# alb32r003x register map
Vendor: ALB; Series: ALB RT SoC
CPU: ALB XF, little endian
Registers are 32-bit, access not given, reset 0x0 unless marked. A register's access mark holds for its fields unless they carry their own. Offsets are from the block's base; [hi:lo] are bit positions.

## CMPSS1
Base 0x21030000
Same registers: CMPSS2 0x21030400, CMPSS3 0x21030800, CMPSS4 0x21030C00
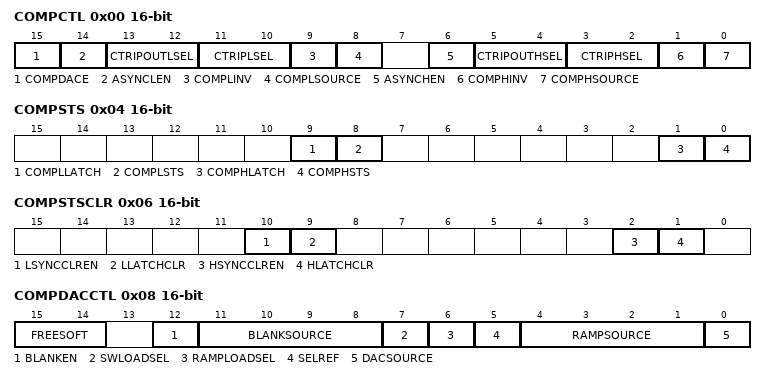
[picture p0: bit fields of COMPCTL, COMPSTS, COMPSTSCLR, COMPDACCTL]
0x00 COMPCTL 16-bit
  [15] COMPDACE — Comparator/DAC enable.
  [14] ASYNCLEN — Low comparator asynchronous path enable. Allows asynchronous
  [13:12] CTRIPOUTLSEL — Low comparator CTRIPOUTL source select.
  [11:10] CTRIPLSEL — Low comparator CTRIPL source select.
  [9] COMPLINV — Low comparator output invert.
  [8] COMPLSOURCE — Low comparator input source.
  [6] ASYNCHEN — High comparator asynchronous path enable. Allows asynchronous
  [5:4] CTRIPOUTHSEL — High comparator CTRIPOUTH source select.
  [3:2] CTRIPHSEL — High comparator CTRIPH source select.
  [1] COMPHINV — High comparator output invert.
  [0] COMPHSOURCE — High comparator input source.
0x02 COMPHYSCTL 16-bit
  [3:0] COMPHYS — Comparator hysteresis. Sets the amount of hysteresis on the
0x04 COMPSTS 16-bit
  [9] COMPLLATCH — Latched value of low comparator digital filter output
  [8] COMPLSTS — Low comparator digital filter output
  [1] COMPHLATCH — Latched value of high comparator digital filter output
  [0] COMPHSTS — High comparator digital filter output
0x06 COMPSTSCLR 16-bit
  [10] LSYNCCLREN — Low comparator latch EPWMSYNCPER clear. Enable
  [9] LLATCHCLR — Low comparator latch software clear. Perform software reset of
  [2] HSYNCCLREN — High comparator latch EPWMSYNCPER clear. Enable
  [1] HLATCHCLR — High comparator latch software clear. Perform software reset of high
0x08 COMPDACCTL 16-bit
  [15:14] FREESOFT — Free-run or software-run emulation behavior. Behavior of the ramp
  [12] BLANKEN — EPWMBLANK enable. This bit enables the EPWMBLANK signal.
  [11:8] BLANKSOURCE — EPWMBLANK source select. This bit field determines which
  [7] SWLOADSEL — Software load select. Determines whether DACxVALA is updated
  [6] RAMPLOADSEL — Ramp load select. Determines whether RAMPSTS is
  [5] SELREF — DAC reference select. Determines which voltage supply is used as
  [4:1] RAMPSOURCE — EPWMSYNCPER source select. Determines which
  [0] DACSOURCE — DAC source select. Determines whether DACHVALA is updated from
0x0C DACHVALS 16-bit
  [11:0] DACHVALS — High DAC shadow value. When COMPDACCTL[DACSOURCE]=0,
0x0E DACHVALA 16-bit
  [11:0] DACHVALA — High DAC active value. Value that is actively driven by the high DAC.
0x10 RAMPMAXREFA 16-bit
  [15:0] RAMPMAXREFA — Ramp maximum reference active value. Latched value to be loaded
0x14 RAMPMAXREFS 16-bit
  [15:0] RAMPMAXREFS — Ramp maximum reference shadow. Unlatched value to be loaded
0x18 RAMPDECVALA 16-bit
  [15:0] RAMPDECVALA — Ramp decrement value active. Latched value that will be subtracted
0x1C RAMPDECVALS 16-bit
  [15:0] RAMPDECVALS — Ramp decrement value shadow. Unlatched value to be loaded into
0x20 RAMPSTS 16-bit
  [15:0] RAMPVALUE — Ramp value. Present value of ramp generator.
0x24 DACLVALS 16-bit
  [11:0] DACLVALS — Low DAC shadow value. value to be loaded into DACLVALA on the
0x26 DACLVALA 16-bit
  [11:0] DACLVALA — Low DAC active value. Value that is actively driven by the low DAC.
0x28 RAMPDLYA 16-bit
  [12:0] RAMPDLYA — Ramp delay active value. Latched value of the number of cycles
0x2A RAMPDLYS 16-bit
  [12:0] RAMPDLYS — Ramp delay shadow value. Unlatched value to be loaded into
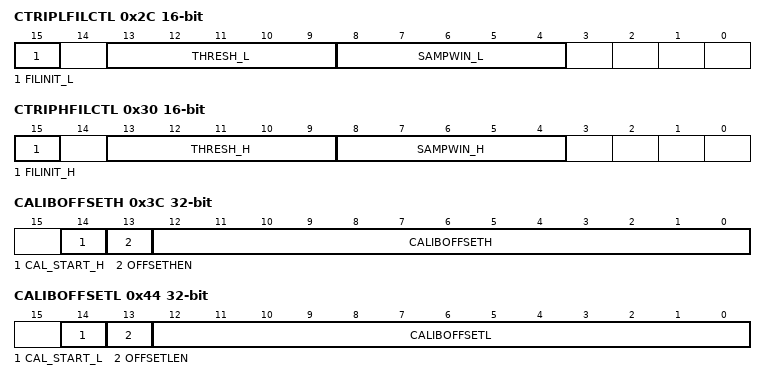
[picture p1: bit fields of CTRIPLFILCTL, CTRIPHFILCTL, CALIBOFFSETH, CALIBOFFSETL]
0x2C CTRIPLFILCTL 16-bit
  [15] FILINIT_L — Low filter initialization.
  [13:9] THRESH_L — Low filter majority voting threshold. At least THRESH samples of the
  [8:4] SAMPWIN_L — Low filter sample window size. Number of samples to monitor is
0x2E CTRIPLFILCLKCTL 16-bit
  [15:0] CLKPRESCALE_L — Low filter sample clock prescale. Number of system clocks between
0x30 CTRIPHFILCTL 16-bit
  [15] FILINIT_H — High filter initialization.
  [13:9] THRESH_H — High filter majority voting threshold. At least THRESH samples of the
  [8:4] SAMPWIN_H — High filter sample window size. Number of samples to monitor is
0x32 CTRIPHFILCLKCTL 16-bit
  [15:0] CLKPRESCALE_H — High filter sample clock prescale. Number of system clocks between
0x34 CMPSS_LOCK
0x38 CMPHSETUPTIME
  [31:0] CMPHSETUPTIME — High comparator setup time.
0x3C CALIBOFFSETH
  [14] CAL_START_H — High Compartor Calibration Start
  [13] OFFSETHEN — High Comparator Offset Enable
  [12:0] CALIBOFFSETH — High Comparator Offset Value
0x40 CMPLSETUPTIME
  [31:0] CMPLSETUPTIME — Low comparator setup time.
0x44 CALIBOFFSETL
  [14] CAL_START_L — Low Calibration Start
  [13] OFFSETLEN — Low Comparator Offset Enable
  [12:0] CALIBOFFSETL — Low Comparator Offset Value
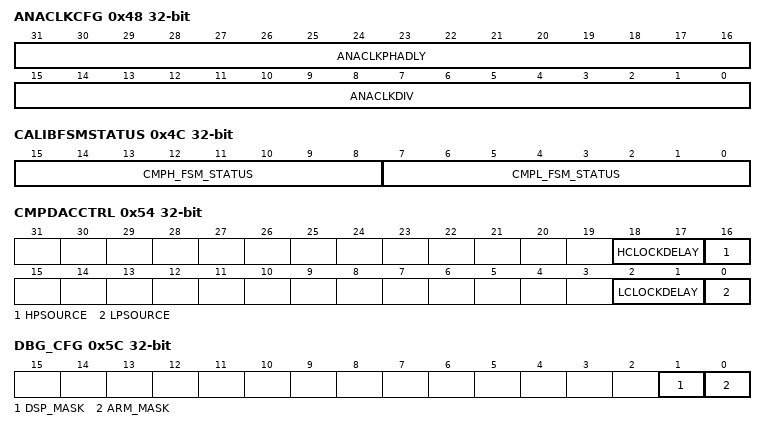
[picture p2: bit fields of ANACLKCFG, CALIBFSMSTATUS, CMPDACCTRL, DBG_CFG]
0x48 ANACLKCFG
  [31:16] ANACLKPHADLY — ANACLK phase delay configuration
  [15:0] ANACLKDIV — ANACLK period configuration
0x4C CALIBFSMSTATUS
  [15:8] CMPH_FSM_STATUS — High Comparator Calibration Current FSM State Value:
  [7:0] CMPL_FSM_STATUS — Low Comparator Calibration Current FSM State Value:
0x50 EPWMBLANKCTRL
  [0] BLANK_INV — EPWMBLANK polarity control
0x54 CMPDACCTRL
  [18:17] HCLOCKDELAY — High inner DAC输入时钟delay
  [16] HPSOURCE — CMP_H Positive输入来源
  [2:1] LCLOCKDELAY — Low inner DAC输入时钟delay
  [0] LPSOURCE — CMP_L Positive输入来源
0x5C DBG_CFG
  [1] DSP_MASK — Configure if the emulation behavior controled by DSP
  [0] ARM_MASK — Configure if the emulation behavior controled by ARM
